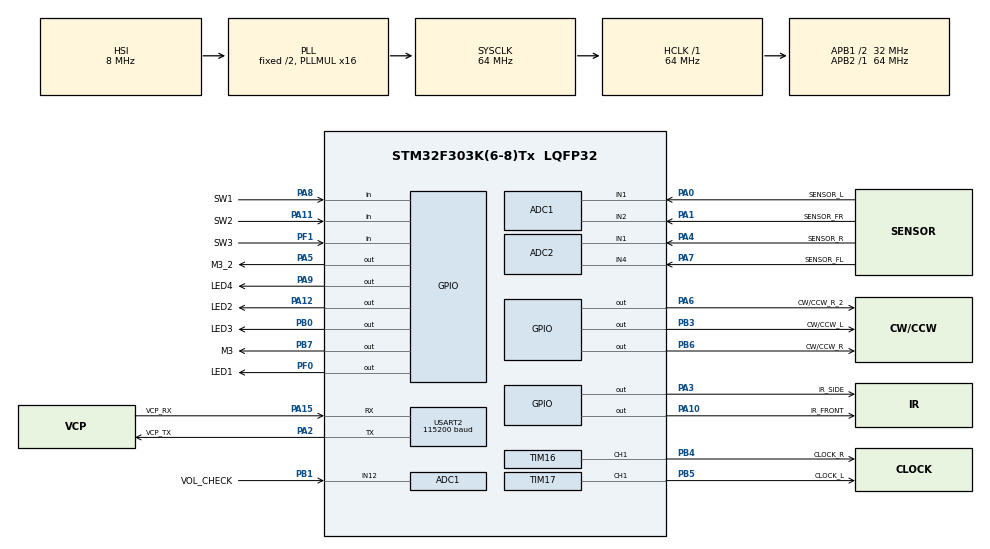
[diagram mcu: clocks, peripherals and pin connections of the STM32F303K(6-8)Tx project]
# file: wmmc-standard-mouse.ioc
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ADC1.Channel-0\#ChannelRegularConversion=ADC_CHANNEL_1
ADC1.Channel-1\#ChannelRegularConversion=ADC_CHANNEL_2
ADC1.Channel-2\#ChannelRegularConversion=ADC_CHANNEL_12
ADC1.DiscontinuousConvMode=ENABLE
ADC1.EnableInjectedConversion=DISABLE
ADC1.NbrOfConversion=3
ADC1.NbrOfConversionFlag=1
ADC1.Offset-0\#ChannelRegularConversion=0
ADC1.Offset-1\#ChannelRegularConversion=0
ADC1.Offset-2\#ChannelRegularConversion=0
ADC1.OffsetNumber-0\#ChannelRegularConversion=ADC_OFFSET_NONE
ADC1.OffsetNumber-1\#ChannelRegularConversion=ADC_OFFSET_NONE
ADC1.OffsetNumber-2\#ChannelRegularConversion=ADC_OFFSET_NONE
ADC1.Rank-0\#ChannelRegularConversion=1
ADC1.Rank-1\#ChannelRegularConversion=2
ADC1.Rank-2\#ChannelRegularConversion=3
ADC1.SamplingTime-0\#ChannelRegularConversion=ADC_SAMPLETIME_1CYCLE_5
ADC1.SamplingTime-1\#ChannelRegularConversion=ADC_SAMPLETIME_1CYCLE_5
ADC1.SamplingTime-2\#ChannelRegularConversion=ADC_SAMPLETIME_1CYCLE_5
ADC1.SamplingTimeOPAMP-1\#ChannelRegularConversion=ADC_SAMPLETIME_61CYCLES_5
ADC1.SamplingTimeOPAMP-2\#ChannelRegularConversion=ADC_SAMPLETIME_61CYCLES_5
ADC1.SubFamily=STM32F303x8
ADC1.master=1
ADC2.Channel-0\#ChannelRegularConversion=ADC_CHANNEL_1
ADC2.Channel-1\#ChannelRegularConversion=ADC_CHANNEL_4
ADC2.DiscontinuousConvMode=ENABLE
ADC2.EnableInjectedConversion=DISABLE
ADC2.NbrOfConversion=2
ADC2.NbrOfConversionFlag=1
ADC2.Offset-0\#ChannelRegularConversion=0
ADC2.Offset-1\#ChannelRegularConversion=0
ADC2.OffsetNumber-0\#ChannelRegularConversion=ADC_OFFSET_NONE
ADC2.OffsetNumber-1\#ChannelRegularConversion=ADC_OFFSET_NONE
ADC2.Rank-0\#ChannelRegularConversion=1
ADC2.Rank-1\#ChannelRegularConversion=2
ADC2.SamplingTime-0\#ChannelRegularConversion=ADC_SAMPLETIME_1CYCLE_5
ADC2.SamplingTime-1\#ChannelRegularConversion=ADC_SAMPLETIME_1CYCLE_5
ADC2.SubFamily=STM32F303x8
Mcu.Family=STM32F3
Mcu.Name=STM32F303K(6-8)Tx
Mcu.Package=LQFP32
NVIC.PriorityGroup=NVIC_PRIORITYGROUP_4
NVIC.TIM1_TRG_COM_TIM17_IRQn=true\:0\:0\:false\:false\:true\:true\:true\:true
NVIC.TIM1_UP_TIM16_IRQn=true\:0\:0\:false\:false\:true\:true\:true\:true
NVIC.TIM6_DAC1_IRQn=true\:0\:0\:false\:false\:true\:true\:true\:true
PA0.GPIO_Label=SENSOR_L
PA0.Mode=IN1-Single-Ended
PA0.Signal=ADC1_IN1
PA1.GPIO_Label=SENSOR_FR
PA1.Mode=IN2-Single-Ended
PA1.Signal=ADC1_IN2
PA10.GPIO_Label=IR_FRONT
PA10.Signal=GPIO_Output
PA11.GPIO_Label=SW2
PA11.GPIO_PuPd=GPIO_PULLUP
PA11.Signal=GPIO_Input
PA12.GPIO_Label=LED2
PA12.Signal=GPIO_Output
PA13.GPIO_Label=SWDIO
PA13.Mode=Serial_Wire
PA13.Signal=SYS_JTMS-SWDIO
PA14.GPIO_Label=SWCLK
PA14.Mode=Serial_Wire
PA14.Signal=SYS_JTCK-SWCLK
PA15.GPIO_Label=VCP_RX
PA15.Mode=Asynchronous
PA15.Signal=USART2_RX
PA2.GPIO_Label=VCP_TX
PA2.Mode=Asynchronous
PA2.Signal=USART2_TX
PA3.GPIO_Label=IR_SIDE
PA3.Signal=GPIO_Output
PA4.GPIO_Label=SENSOR_R
PA4.Mode=IN1-Single-Ended
PA4.Signal=ADC2_IN1
PA5.GPIO_Label=M3_2
PA5.Signal=GPIO_Output
PA6.GPIO_Label=CW/CCW_R_2
PA6.Signal=GPIO_Output
PA7.GPIO_Label=SENSOR_FL
PA7.Mode=IN4-Single-Ended
PA7.Signal=ADC2_IN4
PA8.GPIO_Label=SW1
PA8.GPIO_PuPd=GPIO_PULLUP
PA8.Signal=GPIO_Input
PA9.GPIO_Label=LED4
PA9.GPIO_PuPd=GPIO_NOPULL
PA9.Signal=GPIO_Output
PB0.GPIO_Label=LED3
PB0.Signal=GPIO_Output
PB1.GPIO_Label=VOL_CHECK
PB1.Mode=IN12-Single-Ended
PB1.Signal=ADC1_IN12
PB3.GPIO_Label=CW/CCW_L
PB3.Signal=GPIO_Output
PB4.GPIO_Label=CLOCK_R
PB4.Signal=S_TIM16_CH1
PB5.GPIO_Label=CLOCK_L
PB5.Signal=S_TIM17_CH1
PB6.GPIO_Label=CW/CCW_R
PB6.Signal=GPIO_Output
PB7.GPIO_Label=M3
PB7.GPIO_PuPd=GPIO_NOPULL
PB7.Signal=GPIO_Output
PF0\ /\ OSC_IN.GPIO_Label=LED1
PF0\ /\ OSC_IN.Signal=GPIO_Output
PF1\ /\ OSC_OUT.GPIO_Label=SW3
PF1\ /\ OSC_OUT.GPIO_PuPd=GPIO_PULLUP
PF1\ /\ OSC_OUT.Signal=GPIO_Input
ProjectManager.HeapSize=0x200
ProjectManager.StackSize=0x400
ProjectManager.TargetToolchain=STM32CubeIDE
RCC.AHBFreq_Value=64000000
RCC.APB1CLKDivider=RCC_HCLK_DIV2
RCC.APB1Freq_Value=32000000
RCC.APB1TimFreq_Value=64000000
RCC.APB2Freq_Value=64000000
RCC.APB2TimFreq_Value=64000000
RCC.CortexFreq_Value=64000000
RCC.HCLKFreq_Value=64000000
RCC.HSE_VALUE=8000000
RCC.HSI_VALUE=8000000
RCC.PLLMUL=RCC_PLL_MUL16
RCC.SYSCLKFreq_VALUE=64000000
RCC.SYSCLKSourceVirtual=RCC_SYSCLKSOURCE_PLLCLK
SH.S_TIM16_CH1.0=TIM16_CH1,PWM Generation1 CH1
SH.S_TIM17_CH1.0=TIM17_CH1,PWM Generation1 CH1
TIM16.Channel=TIM_CHANNEL_1
TIM16.Period=0
TIM16.Prescaler=64-1
TIM16.Pulse=25
TIM17.Channel=TIM_CHANNEL_1
TIM17.Period=0
TIM17.Prescaler=64-1
TIM17.Pulse=25
TIM6.Period=4000
TIM6.Prescaler=64-1
USART2.BaudRate=115200
USART2.VirtualMode-Asynchronous=VM_ASYNC
VP_TIM16_VS_ClockSourceINT.Mode=Enable_Timer
VP_TIM17_VS_ClockSourceINT.Mode=Enable_Timer
VP_TIM6_VS_ClockSourceINT.Mode=Enable_Timer
board=NUCLEO-F303K8

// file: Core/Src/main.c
/* USER CODE BEGIN Header */

/************************************************************
    WMMC Nucleoマウス 標準プログラム
    2007~2012     H8/3694f版が運用される
    2013/03/01    LPC向けに移植
    2013/09/20    標準化のため修正
    2017/11/12    STM32向けに移植
    2019/05/01    STM32/CubeHAL向けに移植
    2023/03/XX    Nucleoマウス向けに移植
 ************************************************************/

/**
 ******************************************************************************
 * @file           : main.c
 * @brief          : Main program body
 ******************************************************************************
 * @attention
 *
 * <h2><center>&copy; Copyright (c) 2019 STMicroelectronics.
 * All rights reserved.</center></h2>
 *
 * This software component is licensed by ST under BSD 3-Clause license,
 * the "License"; You may not use this file except in compliance with the
 * License. You may obtain a copy of the License at:
 *                        opensource.org/licenses/BSD-3-Clause
 *
 ******************************************************************************
 */
/* USER CODE END Header */
#include "main.h"

/* USER CODE BEGIN Includes */

#include "app/app_main.h"

/* USER CODE END Includes */

ADC_HandleTypeDef hadc1;
ADC_HandleTypeDef hadc2;

TIM_HandleTypeDef htim6;
TIM_HandleTypeDef htim16;
TIM_HandleTypeDef htim17;

UART_HandleTypeDef huart2;

void SystemClock_Config(void);
static void MX_GPIO_Init(void);
static void MX_ADC1_Init(void);
static void MX_ADC2_Init(void);
static void MX_TIM6_Init(void);
static void MX_TIM16_Init(void);
static void MX_TIM17_Init(void);
static void MX_USART2_UART_Init(void);

int main(void)
{

  /* MCU Configuration--------------------------------------------------------*/

  /* Reset of all peripherals, Initializes the Flash interface and the Systick. */
  HAL_Init();

  /* Configure the system clock */
  SystemClock_Config();

  /* Initialize all configured peripherals */
  MX_GPIO_Init();
  MX_ADC1_Init();
  MX_ADC2_Init();
  MX_TIM6_Init();
  MX_TIM16_Init();
  MX_TIM17_Init();
  MX_USART2_UART_Init();
  /* USER CODE BEGIN 2 */

    // マウスとしての処理はすべて app_main() の中にある（Core/Src/app/app_main.c）。
    // CubeMXが再生成するこのファイルには手書きコードを増やさないこと
    app_main(); // 戻らない
  /* USER CODE END 2 */

  /* Infinite loop */
  while (1)
  {

  }
}

void SystemClock_Config(void)
{
  RCC_OscInitTypeDef RCC_OscInitStruct = {0};
  RCC_ClkInitTypeDef RCC_ClkInitStruct = {0};
  RCC_PeriphCLKInitTypeDef PeriphClkInit = {0};

  /** Initializes the RCC Oscillators according to the specified parameters
  * in the RCC_OscInitTypeDef structure.
  */
  RCC_OscInitStruct.OscillatorType = RCC_OSCILLATORTYPE_HSI;
  RCC_OscInitStruct.HSIState = RCC_HSI_ON;
  RCC_OscInitStruct.HSICalibrationValue = RCC_HSICALIBRATION_DEFAULT;
  RCC_OscInitStruct.PLL.PLLState = RCC_PLL_ON;
  RCC_OscInitStruct.PLL.PLLSource = RCC_PLLSOURCE_HSI;
  RCC_OscInitStruct.PLL.PLLMUL = RCC_PLL_MUL16;
  if (HAL_RCC_OscConfig(&RCC_OscInitStruct) != HAL_OK)
  {
    Error_Handler();
  }

  /** Initializes the CPU, AHB and APB buses clocks
  */
  RCC_ClkInitStruct.ClockType = RCC_CLOCKTYPE_HCLK|RCC_CLOCKTYPE_SYSCLK
                              |RCC_CLOCKTYPE_PCLK1|RCC_CLOCKTYPE_PCLK2;
  RCC_ClkInitStruct.SYSCLKSource = RCC_SYSCLKSOURCE_PLLCLK;
  RCC_ClkInitStruct.AHBCLKDivider = RCC_SYSCLK_DIV1;
  RCC_ClkInitStruct.APB1CLKDivider = RCC_HCLK_DIV2;
  RCC_ClkInitStruct.APB2CLKDivider = RCC_HCLK_DIV1;

  if (HAL_RCC_ClockConfig(&RCC_ClkInitStruct, FLASH_LATENCY_2) != HAL_OK)
  {
    Error_Handler();
  }
  PeriphClkInit.PeriphClockSelection = RCC_PERIPHCLK_ADC12;
  PeriphClkInit.Adc12ClockSelection = RCC_ADC12PLLCLK_DIV1;
  if (HAL_RCCEx_PeriphCLKConfig(&PeriphClkInit) != HAL_OK)
  {
    Error_Handler();
  }
}

static void MX_ADC1_Init(void)
{

  ADC_MultiModeTypeDef multimode = {0};
  ADC_ChannelConfTypeDef sConfig = {0};

  /** Common config
  */
  hadc1.Instance = ADC1;
  hadc1.Init.ClockPrescaler = ADC_CLOCK_ASYNC_DIV1;
  hadc1.Init.Resolution = ADC_RESOLUTION_12B;
  hadc1.Init.ScanConvMode = ADC_SCAN_ENABLE;
  hadc1.Init.ContinuousConvMode = DISABLE;
  hadc1.Init.DiscontinuousConvMode = ENABLE;
  hadc1.Init.NbrOfDiscConversion = 1;
  hadc1.Init.ExternalTrigConvEdge = ADC_EXTERNALTRIGCONVEDGE_NONE;
  hadc1.Init.ExternalTrigConv = ADC_SOFTWARE_START;
  hadc1.Init.DataAlign = ADC_DATAALIGN_RIGHT;
  hadc1.Init.NbrOfConversion = 3;
  hadc1.Init.DMAContinuousRequests = DISABLE;
  hadc1.Init.EOCSelection = ADC_EOC_SINGLE_CONV;
  hadc1.Init.LowPowerAutoWait = DISABLE;
  hadc1.Init.Overrun = ADC_OVR_DATA_OVERWRITTEN;
  if (HAL_ADC_Init(&hadc1) != HAL_OK)
  {
    Error_Handler();
  }

  /** Configure the ADC multi-mode
  */
  multimode.Mode = ADC_MODE_INDEPENDENT;
  if (HAL_ADCEx_MultiModeConfigChannel(&hadc1, &multimode) != HAL_OK)
  {
    Error_Handler();
  }

  /** Configure Regular Channel
  */
  sConfig.Channel = ADC_CHANNEL_1;
  sConfig.Rank = ADC_REGULAR_RANK_1;
  sConfig.SingleDiff = ADC_SINGLE_ENDED;
  sConfig.SamplingTime = ADC_SAMPLETIME_1CYCLE_5;
  sConfig.OffsetNumber = ADC_OFFSET_NONE;
  sConfig.Offset = 0;
  if (HAL_ADC_ConfigChannel(&hadc1, &sConfig) != HAL_OK)
  {
    Error_Handler();
  }

  /** Configure Regular Channel
  */
  sConfig.Channel = ADC_CHANNEL_2;
  sConfig.Rank = ADC_REGULAR_RANK_2;
  if (HAL_ADC_ConfigChannel(&hadc1, &sConfig) != HAL_OK)
  {
    Error_Handler();
  }

  /** Configure Regular Channel
  */
  sConfig.Channel = ADC_CHANNEL_12;
  sConfig.Rank = ADC_REGULAR_RANK_3;
  if (HAL_ADC_ConfigChannel(&hadc1, &sConfig) != HAL_OK)
  {
    Error_Handler();
  }

}

static void MX_ADC2_Init(void)
{

  ADC_ChannelConfTypeDef sConfig = {0};

  /** Common config
  */
  hadc2.Instance = ADC2;
  hadc2.Init.ClockPrescaler = ADC_CLOCK_ASYNC_DIV1;
  hadc2.Init.Resolution = ADC_RESOLUTION_12B;
  hadc2.Init.ScanConvMode = ADC_SCAN_ENABLE;
  hadc2.Init.ContinuousConvMode = DISABLE;
  hadc2.Init.DiscontinuousConvMode = ENABLE;
  hadc2.Init.NbrOfDiscConversion = 1;
  hadc2.Init.ExternalTrigConvEdge = ADC_EXTERNALTRIGCONVEDGE_NONE;
  hadc2.Init.ExternalTrigConv = ADC_SOFTWARE_START;
  hadc2.Init.DataAlign = ADC_DATAALIGN_RIGHT;
  hadc2.Init.NbrOfConversion = 2;
  hadc2.Init.DMAContinuousRequests = DISABLE;
  hadc2.Init.EOCSelection = ADC_EOC_SINGLE_CONV;
  hadc2.Init.LowPowerAutoWait = DISABLE;
  hadc2.Init.Overrun = ADC_OVR_DATA_OVERWRITTEN;
  if (HAL_ADC_Init(&hadc2) != HAL_OK)
  {
    Error_Handler();
  }

  /** Configure Regular Channel
  */
  sConfig.Channel = ADC_CHANNEL_1;
  sConfig.Rank = ADC_REGULAR_RANK_1;
  sConfig.SingleDiff = ADC_SINGLE_ENDED;
  sConfig.SamplingTime = ADC_SAMPLETIME_1CYCLE_5;
  sConfig.OffsetNumber = ADC_OFFSET_NONE;
  sConfig.Offset = 0;
  if (HAL_ADC_ConfigChannel(&hadc2, &sConfig) != HAL_OK)
  {
    Error_Handler();
  }

  /** Configure Regular Channel
  */
  sConfig.Channel = ADC_CHANNEL_4;
  sConfig.Rank = ADC_REGULAR_RANK_2;
  if (HAL_ADC_ConfigChannel(&hadc2, &sConfig) != HAL_OK)
  {
    Error_Handler();
  }

}

static void MX_TIM6_Init(void)
{

  TIM_MasterConfigTypeDef sMasterConfig = {0};

  htim6.Instance = TIM6;
  htim6.Init.Prescaler = 64-1;
  htim6.Init.CounterMode = TIM_COUNTERMODE_UP;
  htim6.Init.Period = 4000;
  htim6.Init.AutoReloadPreload = TIM_AUTORELOAD_PRELOAD_DISABLE;
  if (HAL_TIM_Base_Init(&htim6) != HAL_OK)
  {
    Error_Handler();
  }
  sMasterConfig.MasterOutputTrigger = TIM_TRGO_RESET;
  sMasterConfig.MasterSlaveMode = TIM_MASTERSLAVEMODE_DISABLE;
  if (HAL_TIMEx_MasterConfigSynchronization(&htim6, &sMasterConfig) != HAL_OK)
  {
    Error_Handler();
  }

}

static void MX_TIM16_Init(void)
{

  TIM_OC_InitTypeDef sConfigOC = {0};
  TIM_BreakDeadTimeConfigTypeDef sBreakDeadTimeConfig = {0};

  htim16.Instance = TIM16;
  htim16.Init.Prescaler = 64-1;
  htim16.Init.CounterMode = TIM_COUNTERMODE_UP;
  htim16.Init.Period = 0;
  htim16.Init.ClockDivision = TIM_CLOCKDIVISION_DIV1;
  htim16.Init.RepetitionCounter = 0;
  htim16.Init.AutoReloadPreload = TIM_AUTORELOAD_PRELOAD_DISABLE;
  if (HAL_TIM_Base_Init(&htim16) != HAL_OK)
  {
    Error_Handler();
  }
  if (HAL_TIM_PWM_Init(&htim16) != HAL_OK)
  {
    Error_Handler();
  }
  sConfigOC.OCMode = TIM_OCMODE_PWM1;
  sConfigOC.Pulse = 25;
  sConfigOC.OCPolarity = TIM_OCPOLARITY_HIGH;
  sConfigOC.OCNPolarity = TIM_OCNPOLARITY_HIGH;
  sConfigOC.OCFastMode = TIM_OCFAST_DISABLE;
  sConfigOC.OCIdleState = TIM_OCIDLESTATE_RESET;
  sConfigOC.OCNIdleState = TIM_OCNIDLESTATE_RESET;
  if (HAL_TIM_PWM_ConfigChannel(&htim16, &sConfigOC, TIM_CHANNEL_1) != HAL_OK)
  {
    Error_Handler();
  }
  sBreakDeadTimeConfig.OffStateRunMode = TIM_OSSR_DISABLE;
  sBreakDeadTimeConfig.OffStateIDLEMode = TIM_OSSI_DISABLE;
  sBreakDeadTimeConfig.LockLevel = TIM_LOCKLEVEL_OFF;
  sBreakDeadTimeConfig.DeadTime = 0;
  sBreakDeadTimeConfig.BreakState = TIM_BREAK_DISABLE;
  sBreakDeadTimeConfig.BreakPolarity = TIM_BREAKPOLARITY_HIGH;
  sBreakDeadTimeConfig.BreakFilter = 0;
  sBreakDeadTimeConfig.AutomaticOutput = TIM_AUTOMATICOUTPUT_DISABLE;
  if (HAL_TIMEx_ConfigBreakDeadTime(&htim16, &sBreakDeadTimeConfig) != HAL_OK)
  {
    Error_Handler();
  }
  HAL_TIM_MspPostInit(&htim16);

}

static void MX_TIM17_Init(void)
{

  TIM_OC_InitTypeDef sConfigOC = {0};
  TIM_BreakDeadTimeConfigTypeDef sBreakDeadTimeConfig = {0};

  htim17.Instance = TIM17;
  htim17.Init.Prescaler = 64-1;
  htim17.Init.CounterMode = TIM_COUNTERMODE_UP;
  htim17.Init.Period = 0;
  htim17.Init.ClockDivision = TIM_CLOCKDIVISION_DIV1;
  htim17.Init.RepetitionCounter = 0;
  htim17.Init.AutoReloadPreload = TIM_AUTORELOAD_PRELOAD_DISABLE;
  if (HAL_TIM_Base_Init(&htim17) != HAL_OK)
  {
    Error_Handler();
  }
  if (HAL_TIM_PWM_Init(&htim17) != HAL_OK)
  {
    Error_Handler();
  }
  sConfigOC.OCMode = TIM_OCMODE_PWM1;
  sConfigOC.Pulse = 25;
  sConfigOC.OCPolarity = TIM_OCPOLARITY_HIGH;
  sConfigOC.OCNPolarity = TIM_OCNPOLARITY_HIGH;
  sConfigOC.OCFastMode = TIM_OCFAST_DISABLE;
  sConfigOC.OCIdleState = TIM_OCIDLESTATE_RESET;
  sConfigOC.OCNIdleState = TIM_OCNIDLESTATE_RESET;
  if (HAL_TIM_PWM_ConfigChannel(&htim17, &sConfigOC, TIM_CHANNEL_1) != HAL_OK)
  {
    Error_Handler();
  }
  sBreakDeadTimeConfig.OffStateRunMode = TIM_OSSR_DISABLE;
  sBreakDeadTimeConfig.OffStateIDLEMode = TIM_OSSI_DISABLE;
  sBreakDeadTimeConfig.LockLevel = TIM_LOCKLEVEL_OFF;
  sBreakDeadTimeConfig.DeadTime = 0;
  sBreakDeadTimeConfig.BreakState = TIM_BREAK_DISABLE;
  sBreakDeadTimeConfig.BreakPolarity = TIM_BREAKPOLARITY_HIGH;
  sBreakDeadTimeConfig.BreakFilter = 0;
  sBreakDeadTimeConfig.AutomaticOutput = TIM_AUTOMATICOUTPUT_DISABLE;
  if (HAL_TIMEx_ConfigBreakDeadTime(&htim17, &sBreakDeadTimeConfig) != HAL_OK)
  {
    Error_Handler();
  }
  HAL_TIM_MspPostInit(&htim17);

}

static void MX_USART2_UART_Init(void)
{

  huart2.Instance = USART2;
  huart2.Init.BaudRate = 115200;
  huart2.Init.WordLength = UART_WORDLENGTH_8B;
  huart2.Init.StopBits = UART_STOPBITS_1;
  huart2.Init.Parity = UART_PARITY_NONE;
  huart2.Init.Mode = UART_MODE_TX_RX;
  huart2.Init.HwFlowCtl = UART_HWCONTROL_NONE;
  huart2.Init.OverSampling = UART_OVERSAMPLING_16;
  huart2.Init.OneBitSampling = UART_ONE_BIT_SAMPLE_DISABLE;
  huart2.AdvancedInit.AdvFeatureInit = UART_ADVFEATURE_NO_INIT;
  if (HAL_UART_Init(&huart2) != HAL_OK)
  {
    Error_Handler();
  }

}

static void MX_GPIO_Init(void)
{
  GPIO_InitTypeDef GPIO_InitStruct = {0};

  /* GPIO Ports Clock Enable */
  __HAL_RCC_GPIOF_CLK_ENABLE();
  __HAL_RCC_GPIOA_CLK_ENABLE();
  __HAL_RCC_GPIOB_CLK_ENABLE();

  /*Configure GPIO pin Output Level */
  HAL_GPIO_WritePin(LED1_GPIO_Port, LED1_Pin, GPIO_PIN_RESET);

  /*Configure GPIO pin Output Level */
  HAL_GPIO_WritePin(GPIOA, IR_SIDE_Pin|M3_2_Pin|CW_CCW_R_2_Pin|LED4_Pin
                          |IR_FRONT_Pin|LED2_Pin, GPIO_PIN_RESET);

  /*Configure GPIO pin Output Level */
  HAL_GPIO_WritePin(GPIOB, LED3_Pin|CW_CCW_L_Pin|CW_CCW_R_Pin|M3_Pin, GPIO_PIN_RESET);

  /*Configure GPIO pin : LED1_Pin */
  GPIO_InitStruct.Pin = LED1_Pin;
  GPIO_InitStruct.Mode = GPIO_MODE_OUTPUT_PP;
  GPIO_InitStruct.Pull = GPIO_NOPULL;
  GPIO_InitStruct.Speed = GPIO_SPEED_FREQ_LOW;
  HAL_GPIO_Init(LED1_GPIO_Port, &GPIO_InitStruct);

  /*Configure GPIO pin : SW3_Pin */
  GPIO_InitStruct.Pin = SW3_Pin;
  GPIO_InitStruct.Mode = GPIO_MODE_INPUT;
  GPIO_InitStruct.Pull = GPIO_PULLUP;
  HAL_GPIO_Init(SW3_GPIO_Port, &GPIO_InitStruct);

  /*Configure GPIO pins : IR_SIDE_Pin M3_2_Pin CW_CCW_R_2_Pin LED4_Pin
                           IR_FRONT_Pin LED2_Pin */
  GPIO_InitStruct.Pin = IR_SIDE_Pin|M3_2_Pin|CW_CCW_R_2_Pin|LED4_Pin
                          |IR_FRONT_Pin|LED2_Pin;
  GPIO_InitStruct.Mode = GPIO_MODE_OUTPUT_PP;
  GPIO_InitStruct.Pull = GPIO_NOPULL;
  GPIO_InitStruct.Speed = GPIO_SPEED_FREQ_LOW;
  HAL_GPIO_Init(GPIOA, &GPIO_InitStruct);

  /*Configure GPIO pins : LED3_Pin CW_CCW_L_Pin CW_CCW_R_Pin M3_Pin */
  GPIO_InitStruct.Pin = LED3_Pin|CW_CCW_L_Pin|CW_CCW_R_Pin|M3_Pin;
  GPIO_InitStruct.Mode = GPIO_MODE_OUTPUT_PP;
  GPIO_InitStruct.Pull = GPIO_NOPULL;
  GPIO_InitStruct.Speed = GPIO_SPEED_FREQ_LOW;
  HAL_GPIO_Init(GPIOB, &GPIO_InitStruct);

  /*Configure GPIO pins : SW1_Pin SW2_Pin */
  GPIO_InitStruct.Pin = SW1_Pin|SW2_Pin;
  GPIO_InitStruct.Mode = GPIO_MODE_INPUT;
  GPIO_InitStruct.Pull = GPIO_PULLUP;
  HAL_GPIO_Init(GPIOA, &GPIO_InitStruct);

}

void Error_Handler(void)
{
  /* USER CODE BEGIN Error_Handler_Debug */
    // HALの初期化失敗を黙って続行しないよう、割り込みを止めてLED1を点灯したまま停止する
    __disable_irq();
    HAL_GPIO_WritePin(LED1_GPIO_Port, LED1_Pin, GPIO_PIN_SET);
    while (1) {
    }
  /* USER CODE END Error_Handler_Debug */
}
#ifdef USE_FULL_ASSERT
/**
  * @brief  Reports the name of the source file and the source line number
  *         where the assert_param error has occurred.
  * @param  file: pointer to the source file name
  * @param  line: assert_param error line source number
  * @retval None
  */
void assert_failed(uint8_t *file, uint32_t line)
{
  /* USER CODE BEGIN 6 */
    /* User can add his own implementation to report the file name and line
       number, tex: printf("Wrong parameters value: file %s on line %d\r\n",
       file, line) */
  /* USER CODE END 6 */
}
#endif /* USE_FULL_ASSERT */
